# R7FA0E107 register map
Vendor: Renesas Electronics Corporation; Series: RA0; File version: 1.10.00
CPU: CM23 r1p0, little endian, no MPU, no FPU, VTOR, 2 interrupt priority bits, 64 interrupts
Registers are 16-bit, read-write, reset 0x0 unless marked. A register's access mark holds for its fields unless they carry their own. Offsets are from the block's base; [hi:lo] are bit positions.

## SYSC — System Control
Base 0x4001E000
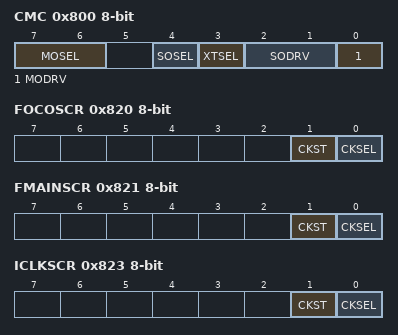
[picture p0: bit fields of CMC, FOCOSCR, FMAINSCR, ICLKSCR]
0x800 CMC 8-bit — Clock Operation Mode Control Register
  [7:6] MOSEL — Main Clock Oscillator Switching
  [4] SOSEL — Sub Clock Oscillator Switching
  [3] XTSEL — Selecting Clock Oscillator
  [2:1] SODRV — Sub,Clock Oscillator Drive Capability Switching
  [0] MODRV — Main Clock Oscillator Drive Capability Switching
0x803 SOMRG 8-bit — Sub,clock Oscillator Margin Check Register
  [1:0] SOSCMRG — Sub Clock Oscillator Margin Check Switching
0x804 MIOTRM 8-bit reset 0x90 — Middle,speed On,chip Oscillator Trimming Register
  [7:0] MIOTRM — MOCO User Trimming
0x805 LIOTRM 8-bit reset 0x80 — Low,speed On,chip Oscillator Trimming Register
  [7:0] LIOTRM — LOCO User Trimming
0x808 HOCOCR 8-bit — High,speed On,chip Oscillator Control Register
  [0] HCSTP — HOCO Stop
0x809 MOCOCR 8-bit reset 0x1 — Middle,speed On,chip Oscillator Control Register
  [0] MCSTP — MOCO Stop
0x80A LOCOCR 8-bit reset 0x1 — Low,speed On,chip Oscillator Control Register
  [0] LCSTP — LOCO Stop
0x80B MOSCCR 8-bit reset 0x1 — Main Clock Oscillator Control Register
  [0] MOSTP — Main Clock Oscillator Stop
0x80C SOSCCR 8-bit reset 0x1 — Sub,clock Oscillator Control Register
  [0] SOSTP — Sub Clock Oscillator Stop
0x810 OSTC 8-bit ro — Oscillation Stabilization Time Counter Status Register
  [7:0] MOST — Selection of the Oscillation Stabilization Time
0x811 OSTS 8-bit reset 0x7 — Oscillation Stabilization Time Select Register
  [2:0] OSTSB — Selection of the Oscillation Stabilization Time
0x812 OSCSF 8-bit ro reset 0x1 — Oscillation Stabilization Flag Register
  [0] HOCOSF — HOCO Clock Oscillation Stabilization Flag
0x818 HOCODIV 8-bit reset 0x3 — High,speed On,chip Oscillator Frequency Select Register
  [2:0] DIV — High,speed On,chip Oscillator Clock Division Ratio
0x819 MOCODIV 8-bit — Middle,speed On,chip Oscillator Frequency Select Register
  [1:0] DIV — Selection of the Middle,speed On,chip Oscillator Clock Frequency
0x81A MOSCDIV 8-bit — MOSC Clock Division Register
  [2:0] DIV — Selection Division Ratio for the MOSC Clock
0x820 FOCOSCR 8-bit — FOCO Clock Source Control Register
  [1] CKST ro — FOCO Clock Source Status
  [0] CKSEL — FOCO Clock Source Select
0x821 FMAINSCR 8-bit — FMAIN Clock Source Control Register
  [1] CKST ro — FMAIN Clock Source Status
  [0] CKSEL — FMAIN Clock Source Select
0x822 FSUBSCR 8-bit — FSUB Clock Source Control Register
  [0] CKSEL — FSUB Clock Source Select
0x823 ICLKSCR 8-bit — ICLK Clock Source Control Register
  [1] CKST ro — ICLK Clock Source Status
  [0] CKSEL — ICLK Clock Source Select
0x824 OSMC 8-bit — Subsystem Clock Supply Mode Control Register
  [4] WUTMMCK0 — Selection of the Operating clock source for the Realtime Clock, 32-bit Interval Timer, Serial Interface UARTA
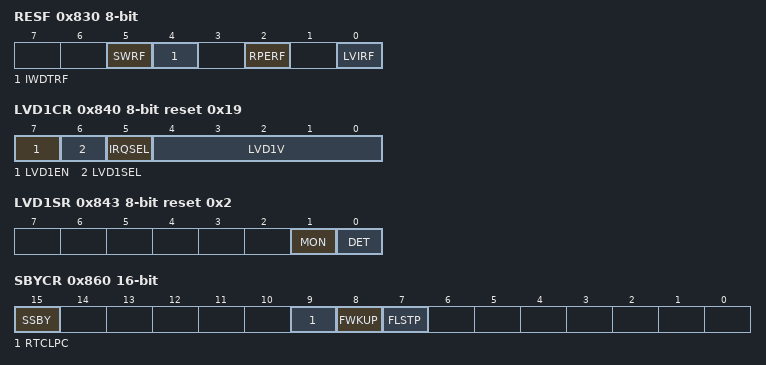
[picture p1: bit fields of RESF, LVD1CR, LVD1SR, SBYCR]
0x830 RESF 8-bit ro (reset mask 0xCA) — Reset Status Flag Register
  [5] SWRF — Internal Reset Request by Software Reset
  [4] IWDTRF — Internal Reset Request by Independent Watchdog Timer (IWDT)
  [2] RPERF — Internal Reset Request by RAM Parity Error
  [0] LVIRF — Internal Reset Request by Voltage Detector (LVD0 or LVD1)
0x831 PORSR 8-bit — Power,On Reset Status Register
  [0] PORF — Checking Occurrence of Power,on Reset
0x840 LVD1CR 8-bit reset 0x19 — Voltage Monitor 1 Circuit Control Register
  [7] LVD1EN — Enabling Operation of LVD1
  [6] LVD1SEL — Operation mode of LVD1
  [5] IRQSEL — Voltage Monitor 1 Interrupt Type Select
  [4:0] LVD1V — Voltage Detection 1 Level Select
0x841 LVD1MKR 8-bit — Voltage Monitor 1 Circuit Mask Register
  [0] MK — Specification of Whether to Enable or Disable Rewriting th LVD1CR Register
0x843 LVD1SR 8-bit reset 0x2 — Voltage Monitor 1 Circuit Status Register
  [1] MON ro — Voltage Monitor 1 Signal Monitor Flag
  [0] DET — Voltage Monitor 1 Voltage Variation Detection Flag
0x860 SBYCR — Standby Control Register
  [15] SSBY — Software Standby Mode Select
  [9] RTCLPC — SOSC Setting in Software Standby Mode or in Snooze Mode
  [8] FWKUP — Setting for Starting the High,speed On,chip Oscillator at the times of release from Software Standby Mode and of Transitions to Snooze Mode
  [7] FLSTP — Flash Mode in Sleep Mode or in Snooze Mode
0x862 PSMCR 8-bit — Power Save Memory Control Register
  [1:0] RAMSD — Operating Mode of the RAM
0x863 SYOCDCR 8-bit — System Control OCD Control Register
  [7] DBGEN — Debugger Enable bit
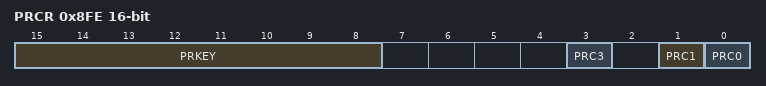
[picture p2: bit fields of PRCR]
0x8FE PRCR — Protect Register
  [15:8] PRKEY wo — PRC Key Code
  [3] PRC3 — Enable writing to the registers related to the LVD
  [1] PRC1 — Enable writing to the registers related to the low power modes
  [0] PRC0 — Enable writing to the registers related to the clock generation circuit
0xC02 MSTPCRA reset 0xFFBF — Module Stop Control Register A
  [6] MSTPA22 — DTC Module Stop
